# ATtiny412 register map
Vendor: Atmel
CPU: other r0p0, little endian, no MPU, no FPU, 4 interrupt priority bits
Registers are 8-bit, read-write, reset 0x0 unless marked. A register's access mark holds for its fields unless they carry their own. Offsets are from the block's base; [hi:lo] are bit positions; {n}, {i} and the like mark numbered series.

## GPIO — General Purpose IO
Base 0x0000001C
{0x0+i} GPIOR{i} (i=0..3) — General Purpose IO Register {i}

## LOCKBIT
Base 0x0000128A
0x00 LOCKBIT — Lock bits
  [7:0] LB — Lock Bits
    58=RWLOCK (Read and write lock); 197=NOLOCK (No locks)

## NVMCTRL — Non-volatile Memory Controller
Base 0x00001000
0x00 CTRLA — Control A
  [2:0] CMD — Command
    0=NONE (No Command); 1=PAGEWRITE (Write page); 2=PAGEERASE (Erase page); 3=PAGEERASEWRITE (Erase and write page); 4=PAGEBUFCLR (Page buffer clear); 5=CHIPERASE; 6=EEERASE (EEPROM erase); 7=FUSEWRITE (Write fuse (PDI only))
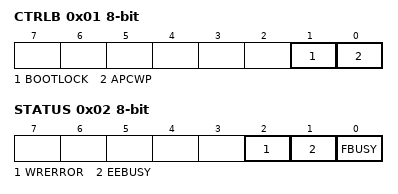
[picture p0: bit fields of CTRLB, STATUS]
0x01 CTRLB — Control B
  [1] BOOTLOCK
  [0] APCWP — Application code write protect
0x02 STATUS ro
  [2] WRERROR — Write error
  [1] EEBUSY — EEPROM busy
  [0] FBUSY — Flash busy
0x03 INTCTRL — Interrupt Control
  [0] EEREADY — EEPROM Ready
0x04 INTFLAGS — Interrupt Flags
  [0] EEREADY — EEPROM Ready
0x06 DATA 16-bit (reset mask 0xFF)
0x08 ADDR 16-bit (reset mask 0xFF) — Address

## PORTA — I/O Ports
Base 0x00000400
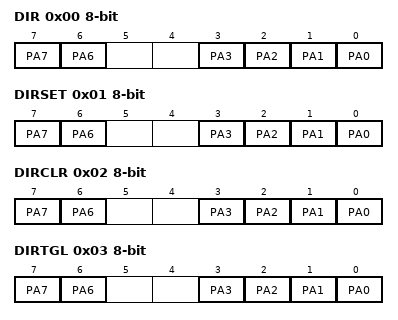
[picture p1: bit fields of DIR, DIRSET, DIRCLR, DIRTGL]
0x00 DIR — Data Direction
  [7] PA7 — Pin A7
  [6] PA6 — Pin A6
  [n] PA{n} (n=0..3) — Pin A{n}
0x01 DIRSET — Data Direction Set
  [7] PA7 — Pin A7
  [6] PA6 — Pin A6
  [n] PA{n} (n=0..3) — Pin A{n}
0x02 DIRCLR — Data Direction Clear
  [7] PA7 — Pin A7
  [6] PA6 — Pin A6
  [n] PA{n} (n=0..3) — Pin A{n}
0x03 DIRTGL — Data Direction Toggle
  [7] PA7 — Pin A7
  [6] PA6 — Pin A6
  [n] PA{n} (n=0..3) — Pin A{n}
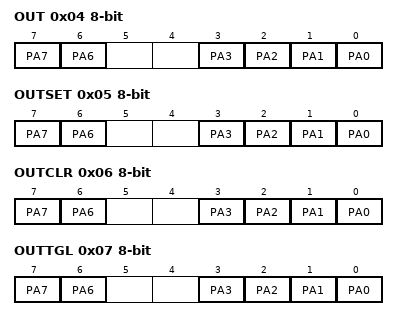
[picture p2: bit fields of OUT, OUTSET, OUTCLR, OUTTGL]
0x04 OUT — Output Value
  [7] PA7 — Pin A7
  [6] PA6 — Pin A6
  [n] PA{n} (n=0..3) — Pin A{n}
0x05 OUTSET — Output Value Set
  [7] PA7 — Pin A7
  [6] PA6 — Pin A6
  [n] PA{n} (n=0..3) — Pin A{n}
0x06 OUTCLR — Output Value Clear
  [7] PA7 — Pin A7
  [6] PA6 — Pin A6
  [n] PA{n} (n=0..3) — Pin A{n}
0x07 OUTTGL — Output Value Toggle
  [7] PA7 — Pin A7
  [6] PA6 — Pin A6
  [n] PA{n} (n=0..3) — Pin A{n}
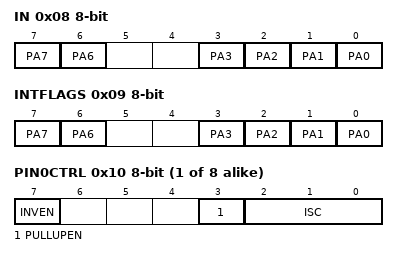
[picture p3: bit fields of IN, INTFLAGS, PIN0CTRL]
0x08 IN — Input Value
  [7] PA7 — Pin A7
  [6] PA6 — Pin A6
  [n] PA{n} (n=0..3) — Pin A{n}
0x09 INTFLAGS — Interrupt Flags
  [7] PA7 — Pin A7
  [6] PA6 — Pin A6
  [n] PA{n} (n=0..3) — Pin A{n}
{0x10+i} PIN{i}CTRL (i=0..7) — Pin {i} Control
  [7] INVEN — Inverted I/O Enable
  [3] PULLUPEN — Pullup enable
  [2:0] ISC — Input/Sense Configuration
    0=INTDISABLE (Iterrupt disabled but input buffer enabled); 1=BOTHEDGES (Sense Both Edges); 2=RISING (Sense Rising Edge); 3=FALLING (Sense Falling Edge); 4=INPUT_DISABLE (Digital Input Buffer disabled); 5=LEVEL (Sense low Level)

## PORTMUX — Port Multiplexer
Base 0x00000200
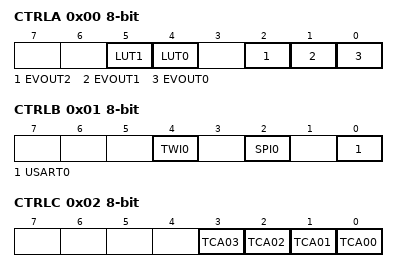
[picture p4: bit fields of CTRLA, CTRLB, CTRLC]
0x00 CTRLA — Port Multiplexer Control A
  [5] LUT1 — Configurable Custom Logic LUT1
    0=DEFAULT (Default pin); 1=ALTERNATE (Alternate pin)
  [4] LUT0 — Configurable Custom Logic LUT0
    0=DEFAULT (Default pin); 1=ALTERNATE (Alternate pin)
  [2] EVOUT2 — Event Output 2
  [1] EVOUT1 — Event Output 1
  [0] EVOUT0 — Event Output 0
0x01 CTRLB — Port Multiplexer Control B
  [all] fields
    0=DEFAULT (Default pins); 1=ALTERNATE (Alternate pins)
  [4] TWI0 — Port Multiplexer TWI0
  [2] SPI0 — Port Multiplexer SPI0
  [0] USART0 — Port Multiplexer USART0
0x02 CTRLC — Port Multiplexer Control C
  [all] fields
    0=DEFAULT (Default pin); 1=ALTERNATE (Alternate pin)
  [3] TCA03 — Port Multiplexer TCA0 Output 3
  [2] TCA02 — Port Multiplexer TCA0 Output 2
  [1] TCA01 — Port Multiplexer TCA0 output 1
  [0] TCA00 — Port Multiplexer TCA0 Output 0
0x03 CTRLD — Port Multiplexer Control D
  [0] TCB0 — Port Multiplexer TCB
    0=DEFAULT (Default pin); 1=ALTERNATE (Alternate pin)

## RSTCTRL — Reset controller
Base 0x00000040
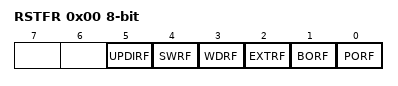
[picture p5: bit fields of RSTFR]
0x00 RSTFR — Reset Flags
  [5] UPDIRF — UPDI Reset flag
  [4] SWRF — Software Reset flag
  [3] WDRF — Watch dog Reset flag
  [2] EXTRF — External Reset flag
  [1] BORF — Brown out detector Reset flag
  [0] PORF — Power on Reset flag
0x01 SWRR — Software Reset
  [0] SWRE — Software reset enable
